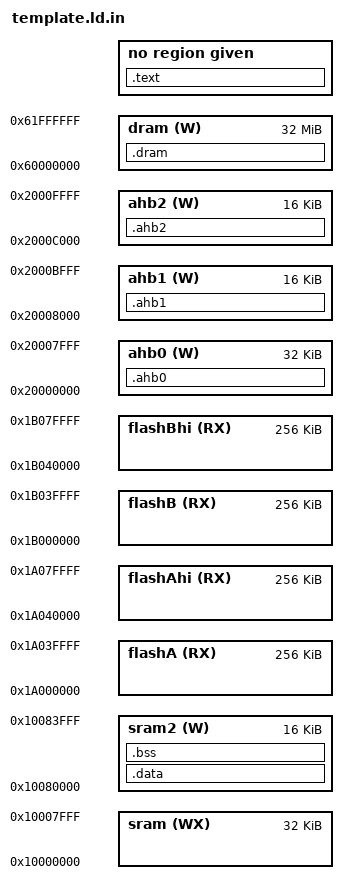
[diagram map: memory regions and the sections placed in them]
MEMORY {
  sram (WX) : ORIGIN = 0x10000000, LENGTH = 32K
  /* sram2 is actually 40K but leave room for the stack.  */
  sram2 (W) : ORIGIN = 0x10080000, LENGTH = 16K

  /* We divide each flash segment into two halves so we can write a second
   * image for testing.  */
  flashA (RX) : ORIGIN = 0x1a000000, LENGTH = 256K
  flashB (RX) : ORIGIN = 0x1b000000, LENGTH = 256K
  flashAhi (RX) : ORIGIN = 0x1a040000, LENGTH = 256K
  flashBhi (RX) : ORIGIN = 0x1b040000, LENGTH = 256K
  ahb0 (W) : ORIGIN = 0x20000000, LENGTH = 32K
  ahb1 (W) : ORIGIN = 0x20008000, LENGTH = 16K
  ahb2 (W) : ORIGIN = 0x2000c000, LENGTH = 16K
  dram (W) : ORIGIN = 0x60000000, LENGTH = 32M
}

SECTIONS
{
  .text : {
     KEEP(*(.start))
     *(.text*)
     *(SORT_BY_ALIGNMENT(.rodata*))
     . = NEXT(4);
     init_script_start = .;
     *(SORT_BY_NAME(init.script*))
     init_script_end = .;
     . = NEXT(4);
  } > @TARGET@
  /* The linker puts initialised data into @TARGET@ and we copy to sram2.  */
  .data : {
     rw_data_start = .;
     *(SORT_BY_ALIGNMENT(.data*))
     rw_data_end = .;
  } > sram2 AT>@TARGET@
  .bss (NOLOAD) : {
     bss_start = .;
     *(SORT_BY_ALIGNMENT(.bss*))
     bss_end = .;
  } > sram2

  rw_data_load = LOADADDR(.data);

  .ahb0 (NOLOAD) : {
     *(SORT_BY_ALIGNMENT(ahb0*))
  } > ahb0
  .ahb1 (NOLOAD) : {
     *(SORT_BY_ALIGNMENT(ahb1*))
  } > ahb1
  .ahb2 (NOLOAD) : {
     *(SORT_BY_ALIGNMENT(ahb2*))
  } > ahb2
  .dram (NOLOAD) : {
     *(SORT_BY_ALIGNMENT(dram*))
  } > dram
}
